# MIMXRT1052 register map
Vendor: nxp.com; File version: 1.0
CPU: CM7 r0p1, little endian, MPU, FPU, VTOR, 4 interrupt priority bits
Registers are 32-bit, read-write, reset 0x0 unless marked. A register's access mark holds for its fields unless they carry their own. Offsets are from the block's base; [hi:lo] are bit positions; {n}, {i} and the like mark numbered series; 'fields as' and 'values as' point back to an identical list.

## LCDIF — LCDIF Register Reference Index
Base 0x402B8000; register names take the prefix LCDIF_
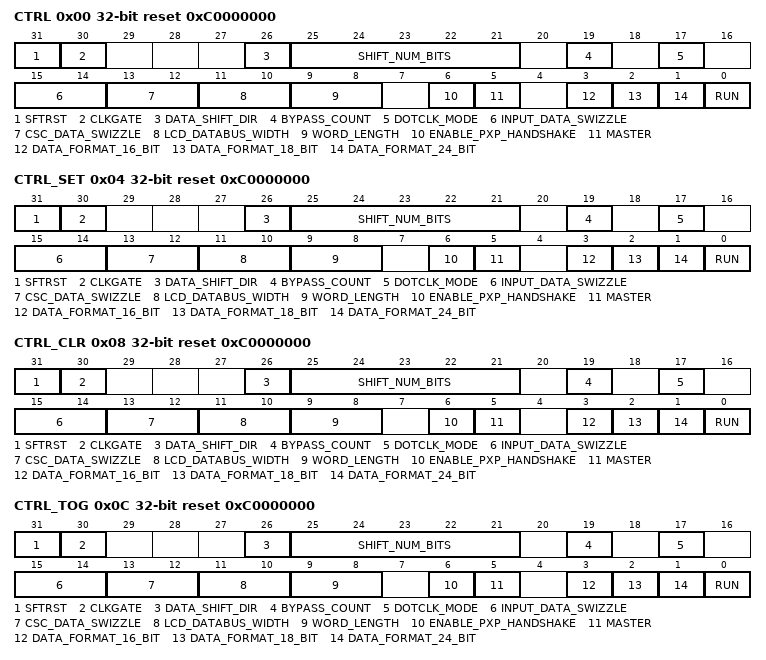
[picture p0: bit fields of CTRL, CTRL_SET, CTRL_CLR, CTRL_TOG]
0x00 CTRL reset 0xC0000000 — LCDIF General Control Register
  [31] SFTRST — This bit must be set to zero to enable normal operation of the LCDIF
  [30] CLKGATE — This bit must be set to zero for normal operation
  [26] DATA_SHIFT_DIR — Use this bit to determine the direction of shift of transmit data.
    0=TXDATA_SHIFT_LEFT (Data to be transmitted is shifted LEFT by SHIFT_NUM_BITS bits.); 1=TXDATA_SHIFT_RIGHT (Data to be transmitted is shifted RIGHT by SHIFT_NUM_BITS bits.)
  [25:21] SHIFT_NUM_BITS — The data to be transmitted is shifted left or right by this number of bits.
  [19] BYPASS_COUNT — When this bit is 0, it means that LCDIF will stop the block operation and turn off the RUN bit after the amount of data indicated by the LCDIF_TRANSFER_COUNT register has been transferred out
  [17] DOTCLK_MODE — Set this bit to 1 to make the hardware go into the DOTCLK mode, i
  [15:14] INPUT_DATA_SWIZZLE — This field specifies how to swap the bytes fetched by the bus master interface
    0=NO_SWAP (No byte swapping.(Little endian)); 1=BIG_ENDIAN_SWAP (Big Endian swap (swap bytes 0,3 and 1,2).); 2=HWD_SWAP (Swap half-words.); 3=HWD_BYTE_SWAP (Swap bytes within each half-word.)
  [13:12] CSC_DATA_SWIZZLE — This field specifies how to swap the bytes after the data has been converted into an internal representation of 24 bits per pixel and before it is transmitted over the LCD interface bus
    values as INPUT_DATA_SWIZZLE
  [11:10] LCD_DATABUS_WIDTH — LCD Data bus transfer width. When LUT enabled, this field should be set to 0x01.
    0=16_BIT (16-bit data bus mode.); 1=8_BIT (8-bit data bus mode.); 2=18_BIT (18-bit data bus mode.); 3=24_BIT (24-bit data bus mode.)
  [9:8] WORD_LENGTH — Input data format.
    0=16_BIT (Input data is 16 bits per pixel.); 1=8_BIT (Input data is 8 bits wide.); 2=18_BIT (Input data is 18 bits per pixel.); 3=24_BIT (Input data is 24 bits per pixel.)
  [6] ENABLE_PXP_HANDSHAKE — If this bit is set and LCDIF_MASTER bit is set, the LCDIF will act as bus master and the handshake mechanism between LCDIF and PXP will be turned on
  [5] MASTER — Set this bit to make the LCDIF act as a bus master.
  [3] DATA_FORMAT_16_BIT — When this bit is 1 and WORD_LENGTH = 0, it implies that the 16-bit data is in ARGB555 format
  [2] DATA_FORMAT_18_BIT — Used only when WORD_LENGTH = 2, i.e. 18-bit.
    0=LOWER_18_BITS_VALID (Data input to the block is in 18 bpp format, such that lower 18 bits contain RGB 666 and upper 14 bits do not contain any useful data.); 1=UPPER_18_BITS_VALID (Data input to the block is in 18 bpp format, such that upper 18 bits contain RGB 666 and lower 14 bits do not contain any useful data.)
  [1] DATA_FORMAT_24_BIT — Used only when WORD_LENGTH = 3, i
    0=ALL_24_BITS_VALID (Data input to the block is in 24 bpp format, such that all RGB 888 data is contained in 24 bits.); 1=DROP_UPPER_2_BITS_PER_BYTE (Data input to the block is actually RGB 18 bpp, but there is 1 color per byte, hence the upper 2 bits in each byte do not contain any useful data, and should be dropped.)
  [0] RUN — When this bit is set by software, the LCDIF will begin transferring data between the SoC and the display
0x04 CTRL_SET reset 0xC0000000 — LCDIF General Control Register
  fields as CTRL
0x08 CTRL_CLR reset 0xC0000000 — LCDIF General Control Register
  fields as CTRL
0x0C CTRL_TOG reset 0xC0000000 — LCDIF General Control Register
  fields as CTRL
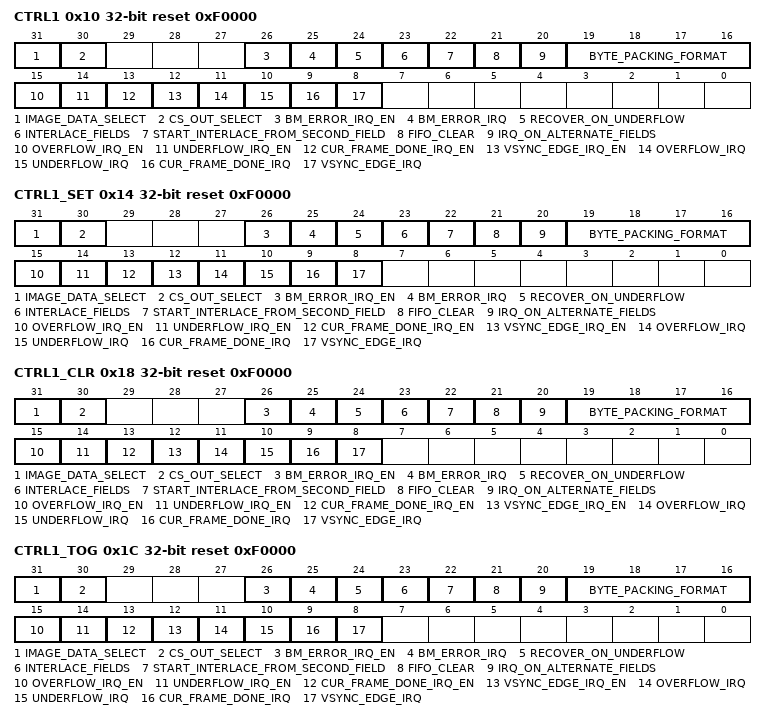
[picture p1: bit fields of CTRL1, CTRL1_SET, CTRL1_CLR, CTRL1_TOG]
0x10 CTRL1 reset 0xF0000 — LCDIF General Control1 Register
  [31] IMAGE_DATA_SELECT — Command Mode MIPI image data select bit
  [30] CS_OUT_SELECT — This bit is CS0/CS1 valid select signals
  [26] BM_ERROR_IRQ_EN — This bit is set to enable bus master error interrupt in the LCDIF master mode.
  [25] BM_ERROR_IRQ — This bit is set to indicate that an interrupt is requested by the LCDIF block
    0=NO_REQUEST (No Interrupt Request Pending.); 1=REQUEST (Interrupt Request Pending.)
  [24] RECOVER_ON_UNDERFLOW — Set this bit to enable the LCDIF block to recover in the next field/frame if there was an underflow in the current field/frame
  [23] INTERLACE_FIELDS — Set this bit if it is required that the LCDIF block fetches odd lines in one field and even lines in the other field
  [22] START_INTERLACE_FROM_SECOND_FIELD — The default is to grab the odd lines first and then the even lines
  [21] FIFO_CLEAR — Set this bit to clear all the data in the latency FIFO (LFIFO), TXFIFO and the RXFIFO.
  [20] IRQ_ON_ALTERNATE_FIELDS — If this bit is set, the LCDIF block will assert the cur_frame_done interrupt only on alternate fields, otherwise it will issue the interrupt on both odd and even field
  [19:16] BYTE_PACKING_FORMAT — This bitfield is used to show which data bytes in a 32-bit word are valid
  [15] OVERFLOW_IRQ_EN — This bit is set to enable an overflow interrupt in the TXFIFO in the write mode.
  [14] UNDERFLOW_IRQ_EN — This bit is set to enable an underflow interrupt in the TXFIFO in the write mode.
  [13] CUR_FRAME_DONE_IRQ_EN — This bit is set to 1 enable an interrupt every time the hardware enters in the vertical blanking state
  [12] VSYNC_EDGE_IRQ_EN — This bit is set to enable an interrupt every time the hardware encounters the leading VSYNC edge in the VSYNC and DOTCLK modes, or the beginning of every field in DVI mode
  [11] OVERFLOW_IRQ — This bit is set to indicate that an interrupt is requested by the LCDIF block
    values as BM_ERROR_IRQ
  [10] UNDERFLOW_IRQ — This bit is set to indicate that an interrupt is requested by the LCDIF block
    values as BM_ERROR_IRQ
  [9] CUR_FRAME_DONE_IRQ — This bit is set to indicate that an interrupt is requested by the LCDIF block
    values as BM_ERROR_IRQ
  [8] VSYNC_EDGE_IRQ — This bit is set to indicate that an interrupt is requested by the LCDIF block
    values as BM_ERROR_IRQ
0x14 CTRL1_SET reset 0xF0000 — LCDIF General Control1 Register
  fields as CTRL1
0x18 CTRL1_CLR reset 0xF0000 — LCDIF General Control1 Register
  fields as CTRL1
0x1C CTRL1_TOG reset 0xF0000 — LCDIF General Control1 Register
  fields as CTRL1
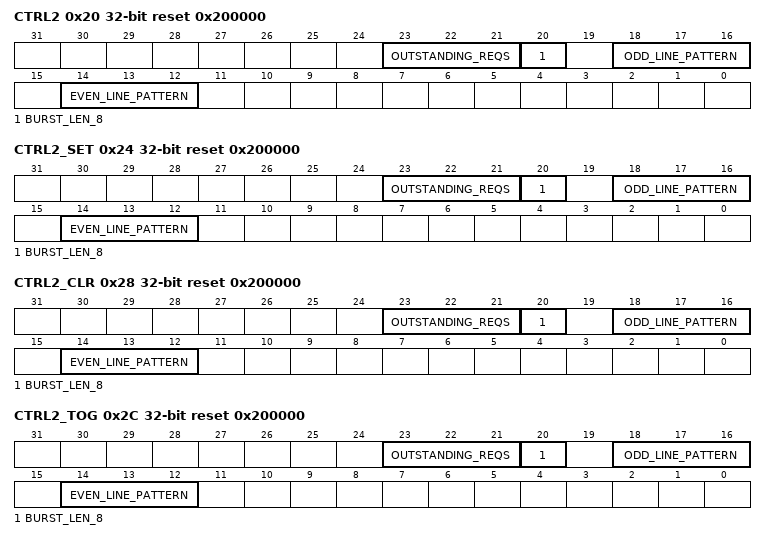
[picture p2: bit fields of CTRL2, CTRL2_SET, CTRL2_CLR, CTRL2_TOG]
0x20 CTRL2 reset 0x200000 — LCDIF General Control2 Register
  [23:21] OUTSTANDING_REQS — This bitfield indicates the maximum number of outstanding transactions that LCDIF should request when it is acting as a bus master
    0=REQ_1; 1=REQ_2; 2=REQ_4; 3=REQ_8; 4=REQ_16
  [20] BURST_LEN_8 — By default, when the LCDIF is in the bus master mode, it will issue AXI bursts of length 16 (except when in packed 24 bpp mode, it will issue bursts of length 15)
  [18:16] ODD_LINE_PATTERN — This field determines the order of the RGB components of each pixel in ODD lines (line numbers 1,3,5,
    0=RGB; 1=RBG; 2=GBR; 3=GRB; 4=BRG; 5=BGR
  [14:12] EVEN_LINE_PATTERN — This field determines the order of the RGB components of each pixel in EVEN lines (line numbers 2,4,6,
    0=RGB; 1=RBG; 2=GBR; 3=GRB; 4=BRG; 5=BGR
0x24 CTRL2_SET reset 0x200000 — LCDIF General Control2 Register
  fields as CTRL2
0x28 CTRL2_CLR reset 0x200000 — LCDIF General Control2 Register
  fields as CTRL2
0x2C CTRL2_TOG reset 0x200000 — LCDIF General Control2 Register
  fields as CTRL2
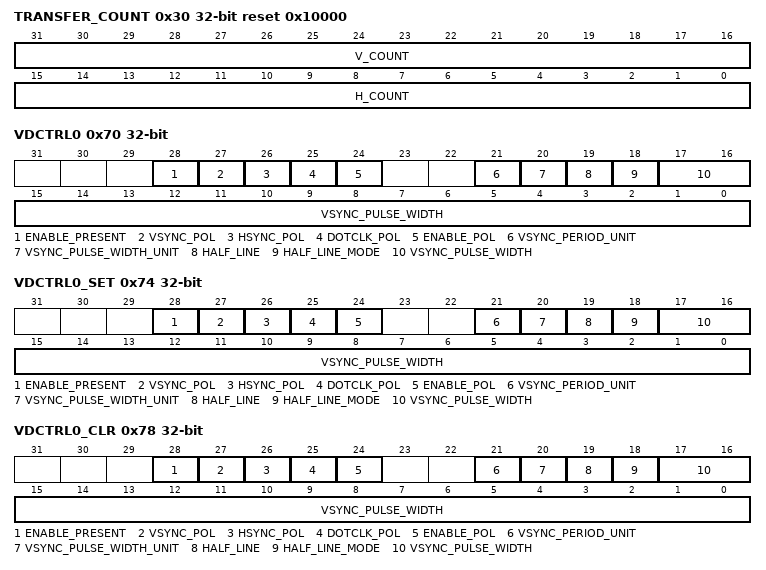
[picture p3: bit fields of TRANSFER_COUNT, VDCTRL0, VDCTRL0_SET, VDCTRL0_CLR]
0x30 TRANSFER_COUNT reset 0x10000 — LCDIF Horizontal and Vertical Valid Data Count Register
  [31:16] V_COUNT — Number of horizontal lines per frame which contain valid data
  [15:0] H_COUNT — Total valid data (pixels) in each horizontal line
0x40 CUR_BUF — LCD Interface Current Buffer Address Register
  [31:0] ADDR — Address of the current frame being transmitted by LCDIF.
0x50 NEXT_BUF — LCD Interface Next Buffer Address Register
  [31:0] ADDR — Address of the next frame that will be transmitted by LCDIF.
0x70 VDCTRL0 — LCDIF VSYNC Mode and Dotclk Mode Control Register0
  [28] ENABLE_PRESENT — Setting this bit to 1 will make the hardware generate the ENABLE signal in the DOTCLK mode, thereby making it the true RGB interface along with the remaining three signals VSYNC, HSYNC and DOTCLK
  [27] VSYNC_POL — Default 0 active low during VSYNC_PULSE_WIDTH time and will be high during the rest of the VSYNC period
  [26] HSYNC_POL — Default 0 active low during HSYNC_PULSE_WIDTH time and will be high during the rest of the HSYNC period
  [25] DOTCLK_POL — Default is data launched at negative edge of DOTCLK and captured at positive edge
  [24] ENABLE_POL — Default 0 active low during valid data transfer on each horizontal line.
  [21] VSYNC_PERIOD_UNIT — Default 0 for counting VSYNC_PERIOD in terms of DISPLAY CLOCK (pix_clk) cycles
  [20] VSYNC_PULSE_WIDTH_UNIT — Default 0 for counting VSYNC_PULSE_WIDTH in terms of DISPLAY CLOCK (pix_clk) cycles
  [19] HALF_LINE — Setting this bit to 1 will make the total VSYNC period equal to the VSYNC_PERIOD field plus half the HORIZONTAL_PERIOD field (i
  [18] HALF_LINE_MODE — When this bit is 0, the first field (VSYNC period) will end in half a horizontal line and the second field will begin with half a horizontal line
  [17:0] VSYNC_PULSE_WIDTH — Number of units for which VSYNC signal is active
0x74 VDCTRL0_SET — LCDIF VSYNC Mode and Dotclk Mode Control Register0
  fields as VDCTRL0
0x78 VDCTRL0_CLR — LCDIF VSYNC Mode and Dotclk Mode Control Register0
  fields as VDCTRL0
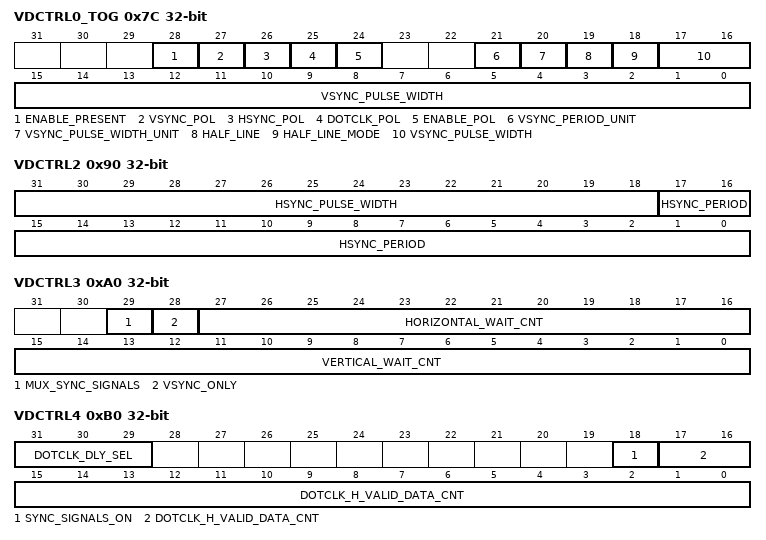
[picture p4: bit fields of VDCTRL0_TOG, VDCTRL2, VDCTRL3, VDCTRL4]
0x7C VDCTRL0_TOG — LCDIF VSYNC Mode and Dotclk Mode Control Register0
  fields as VDCTRL0
0x80 VDCTRL1 — LCDIF VSYNC Mode and Dotclk Mode Control Register1
  [31:0] VSYNC_PERIOD — Total number of units between two positive or two negative edges of the VSYNC signal
0x90 VDCTRL2 — LCDIF VSYNC Mode and Dotclk Mode Control Register2
  [31:18] HSYNC_PULSE_WIDTH — Number of DISPLAY CLOCK (pix_clk) cycles for which HSYNC signal is active.
  [17:0] HSYNC_PERIOD — Total number of DISPLAY CLOCK (pix_clk) cycles between two positive or two negative edges of the HSYNC signal
0xA0 VDCTRL3 — LCDIF VSYNC Mode and Dotclk Mode Control Register3
  [29] MUX_SYNC_SIGNALS — When this bit is set, the LCDIF block will internally mux HSYNC with LCD_D14, DOTCLK with LCD_D13 and ENABLE with LCD_D12, otherwise these signals will go out on separate pins
  [28] VSYNC_ONLY — This bit must be set to 1 in the VSYNC mode of operation, and 0 in the DOTCLK mode of operation.
  [27:16] HORIZONTAL_WAIT_CNT — In the DOTCLK mode, wait for this number of clocks from falling edge (or rising if HSYNC_POL is 1) of HSYNC signal to account for horizontal back porch plus the number of DOTCLKs before the moving picture information begins
  [15:0] VERTICAL_WAIT_CNT — In the VSYNC interface mode, wait for this number of DISPLAY CLOCK (pix_clk) cycles from the falling VSYNC edge (or rising if VSYNC_POL is 1) before starting LCD transactions and is applicable only if WAIT_FOR_VSYNC_EDGE is set
0xB0 VDCTRL4 — LCDIF VSYNC Mode and Dotclk Mode Control Register4
  [31:29] DOTCLK_DLY_SEL — This bitfield selects the amount of time by which the DOTCLK signal should be delayed before coming out of the LCD_DOTCK pin
  [18] SYNC_SIGNALS_ON — Set this field to 1 if the LCD controller requires that the VSYNC or VSYNC/HSYNC/DOTCLK control signals should be active at least one frame before the data transfers actually start and remain active at least one frame after the data transfers end
  [17:0] DOTCLK_H_VALID_DATA_CNT — Total number of DISPLAY CLOCK (pix_clk) cycles on each horizontal line that carry valid data in DOTCLK mode
0x190 BM_ERROR_STAT — Bus Master Error Status Register
  [31:0] ADDR — Virtual address at which bus master error occurred.
0x1A0 CRC_STAT — CRC Status Register
  [31:0] CRC_VALUE — Calculated CRC value
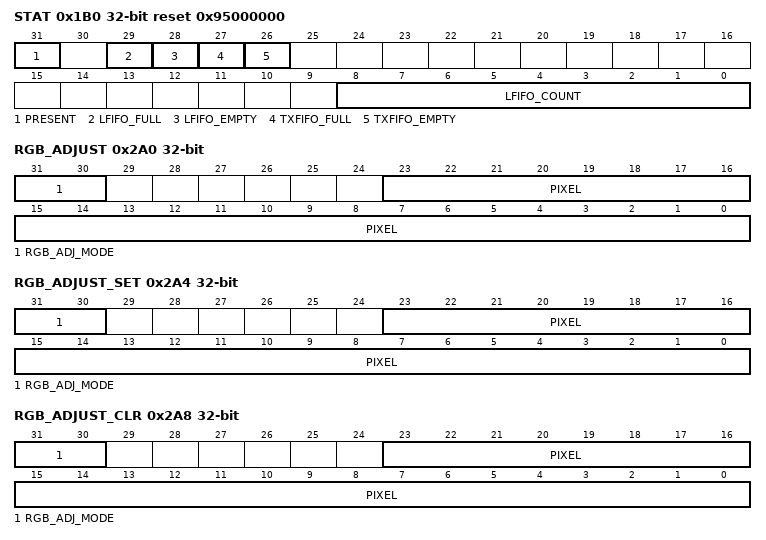
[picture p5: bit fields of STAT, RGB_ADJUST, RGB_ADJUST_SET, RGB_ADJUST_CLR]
0x1B0 STAT ro reset 0x95000000 — LCD Interface Status Register
  [31] PRESENT — 0: LCDIF not present on this product 1: LCDIF is present.
  [29] LFIFO_FULL — Read only view of the signals that indicates LCD LFIFO is full.
  [28] LFIFO_EMPTY — Read only view of the signals that indicates LCD LFIFO is empty.
  [27] TXFIFO_FULL — Read only view of the signals that indicates LCD TXFIFO is full.
  [26] TXFIFO_EMPTY — Read only view of the signals that indicates LCD TXFIFO is empty.
  [8:0] LFIFO_COUNT — Read only view of the current count in Latency buffer (LFIFO).
0x2A0 RGB_ADJUST — RGB Color Range Adjust
  [31:30] RGB_ADJ_MODE — When this bit is set by software, the LCDIF work as sync mode with CSI input.
    0=NO_ADJ (No Adjust); 1=INC_MODE (Increment RGB); 2=DEC_MODE (Decrement RGB); 3=MUT_MODE (Multiply RGB)
  [23:0] PIXEL — Adjust value of RGB color for display.
0x2A4 RGB_ADJUST_SET — RGB Color Range Adjust
  fields as RGB_ADJUST
0x2A8 RGB_ADJUST_CLR — RGB Color Range Adjust
  fields as RGB_ADJUST
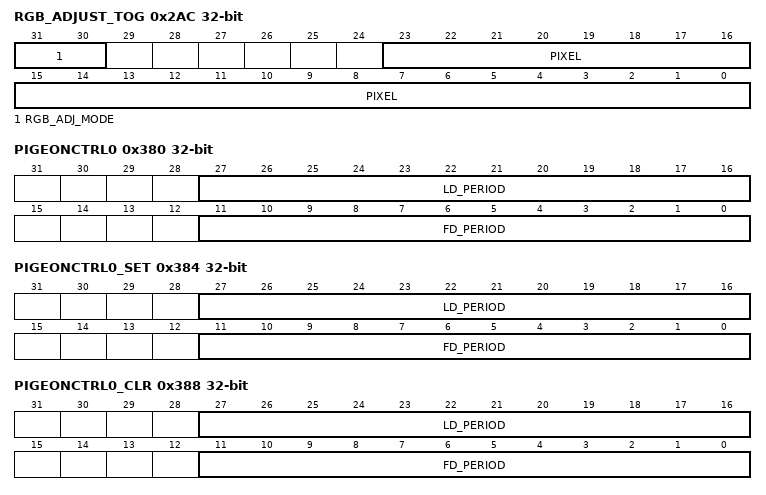
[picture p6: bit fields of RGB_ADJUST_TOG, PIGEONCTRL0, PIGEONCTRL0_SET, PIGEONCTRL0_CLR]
0x2AC RGB_ADJUST_TOG — RGB Color Range Adjust
  fields as RGB_ADJUST
0x380 PIGEONCTRL0 — LCDIF Pigeon Mode Control0 Register
  [27:16] LD_PERIOD — Period of pclk counter during LD phase
  [11:0] FD_PERIOD — Period of line counter during FD phase
0x384 PIGEONCTRL0_SET — LCDIF Pigeon Mode Control0 Register
  fields as PIGEONCTRL0
0x388 PIGEONCTRL0_CLR — LCDIF Pigeon Mode Control0 Register
  fields as PIGEONCTRL0
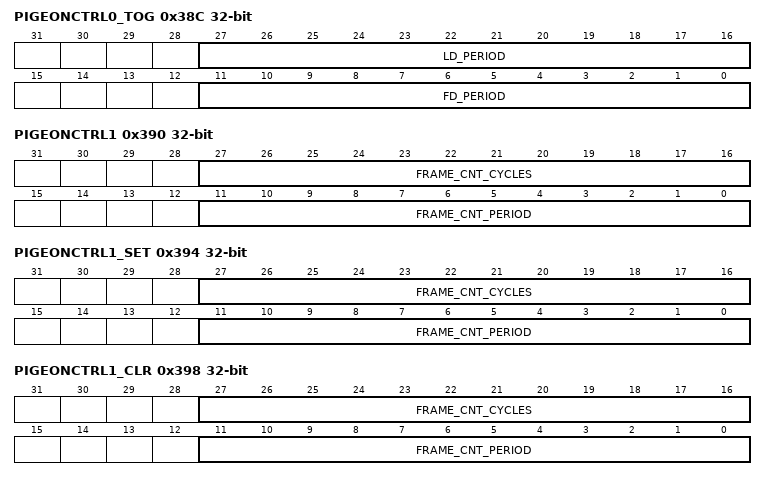
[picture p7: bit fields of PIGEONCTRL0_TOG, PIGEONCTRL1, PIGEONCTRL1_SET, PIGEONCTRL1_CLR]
0x38C PIGEONCTRL0_TOG — LCDIF Pigeon Mode Control0 Register
  fields as PIGEONCTRL0
0x390 PIGEONCTRL1 — LCDIF Pigeon Mode Control1 Register
  [27:16] FRAME_CNT_CYCLES — Max cycles of frame counter
  [11:0] FRAME_CNT_PERIOD — Period of frame counter
0x394 PIGEONCTRL1_SET — LCDIF Pigeon Mode Control1 Register
  fields as PIGEONCTRL1
0x398 PIGEONCTRL1_CLR — LCDIF Pigeon Mode Control1 Register
  fields as PIGEONCTRL1
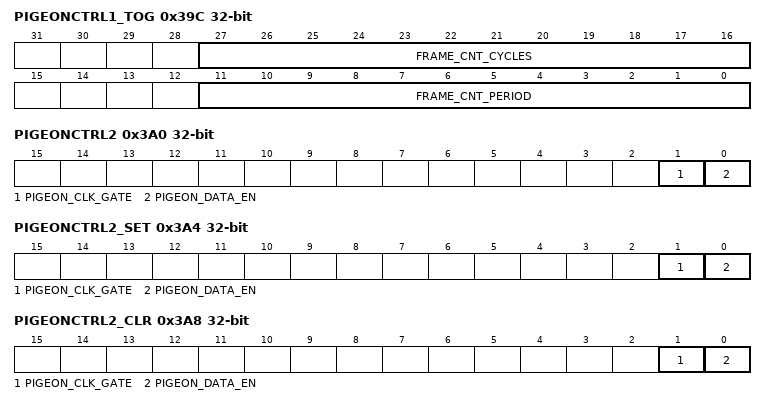
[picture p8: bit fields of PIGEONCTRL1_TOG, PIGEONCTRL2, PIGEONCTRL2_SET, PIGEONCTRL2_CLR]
0x39C PIGEONCTRL1_TOG — LCDIF Pigeon Mode Control1 Register
  fields as PIGEONCTRL1
0x3A0 PIGEONCTRL2 — LCDIF Pigeon Mode Control2 Register
  [1] PIGEON_CLK_GATE — Pigeon mode dot clock gate enable
  [0] PIGEON_DATA_EN — Pigeon mode data enable
0x3A4 PIGEONCTRL2_SET — LCDIF Pigeon Mode Control2 Register
  fields as PIGEONCTRL2
0x3A8 PIGEONCTRL2_CLR — LCDIF Pigeon Mode Control2 Register
  fields as PIGEONCTRL2
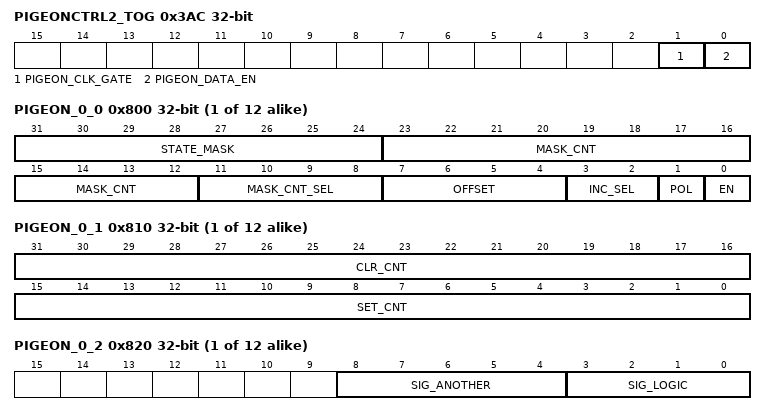
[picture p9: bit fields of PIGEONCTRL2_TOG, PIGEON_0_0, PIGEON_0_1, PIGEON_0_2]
0x3AC PIGEONCTRL2_TOG — LCDIF Pigeon Mode Control2 Register
  fields as PIGEONCTRL2
{0x800+0x40*i} PIGEON_{i}_0 (i=0..11) — Panel Interface Signal Generator Register
  [31:24] STATE_MASK — state_mask = (FS|FB|FD|FE) and (LS|LB|LD|LE) , select any combination of scan states as reference point for local counter to start ticking
    1=FS (FRAME SYNC); 2=FB (FRAME BEGIN); 4=FD (FRAME DATA); 8=FE (FRAME END); 16=LS (LINE SYNC); 32=LB (LINE BEGIN); 64=LD (LINE DATA); 128=LE (LINE END)
  [23:12] MASK_CNT — When the global counter selected through MASK_CNT_SEL matches value in this reg, pigeon local counter start ticking
  [11:8] MASK_CNT_SEL — select global counters as mask condition, use together with MASK_CNT
    0=HSTATE_CNT (pclk counter within one hscan state); 1=HSTATE_CYCLE (pclk cycle within one hscan state); 2=VSTATE_CNT (line counter within one vscan state); 3=VSTATE_CYCLE (line cycle within one vscan state); 4=FRAME_CNT (frame counter); 5=FRAME_CYCLE; 6=HCNT (horizontal counter (pclk counter within one line )); 7=VCNT (vertical counter (line counter within one frame))
  [7:4] OFFSET — offset on pclk unit
  [3:2] INC_SEL — Event to incrment local counter
    0=PCLK; 1=LINE (Line start pulse); 2=FRAME (Frame start pulse); 3=SIG_ANOTHER (Use another signal as tick event)
  [1] POL — Polarity of signal output
    0=ACTIVE_HIGH (Normal Signal (Active high)); 1=ACTIVE_LOW (Inverted signal (Active low))
  [0] EN — Enable pigeon Mode on this signal
{0x810+0x40*i} PIGEON_{i}_1 (i=0..11) — Panel Interface Signal Generator Register
  [31:16] CLR_CNT — Deassert signal output when counter match this value
    0=CLEAR_USING_MASK (Keep active until mask off)
  [15:0] SET_CNT — Assert signal output when counter match this value
    0=START_ACTIVE (Start as active)
{0x820+0x40*i} PIGEON_{i}_2 (i=0..11) — Panel Interface Signal Generator Register
  [8:4] SIG_ANOTHER — Select another signal for logic operation or as mask or counter tick event
    0=CLEAR_USING_MASK (Keep active until mask off)
  [3:0] SIG_LOGIC — Logic operation with another signal: DIS/AND/OR/COND
    0=DIS (No logic operation); 1=AND (sigout = sig_another AND this_sig); 2=OR (sigout = sig_another OR this_sig); 3=MASK (mask = sig_another AND other_masks)
0xB00 LUT_CTRL reset 0x1 — Look Up Table Control Register
  [0] LUT_BYPASS — Setting this bit will bypass the LUT memory resource completely
0xB10 LUT0_ADDR — Lookup Table 0 Index Register
  [7:0] ADDR — LUT indexed address pointer
0xB20 LUT0_DATA — Lookup Table 0 Data Register
  [31:0] DATA — Writing this field will load 4 bytes, aligned to four byte boundaries, of data indexed by the ADDR field of the REG_LUT_CTRL register
0xB30 LUT1_ADDR — Lookup Table 1 Index Register
  [7:0] ADDR — LUT indexed address pointer
0xB40 LUT1_DATA — Lookup Table 1 Data Register
  fields as LUT0_DATA
